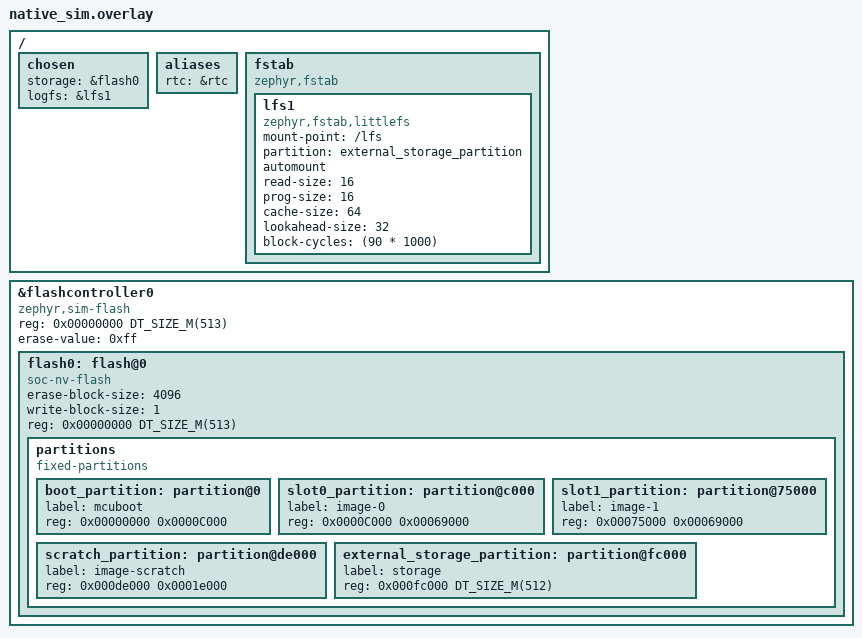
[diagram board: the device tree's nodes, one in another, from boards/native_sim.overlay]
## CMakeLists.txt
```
#-------------------------------------------------------------------------------
# Backplane Power Module Application
#
# Copyright (c) 2023 Launch Initiative
# SPDX-License-Identifier: Apache-2.0

set(FSW_ROOT ${CMAKE_CURRENT_SOURCE_DIR}/../../..)
include(${FSW_ROOT}/cmake/Autocoders.cmake)
include(${FSW_ROOT}/cmake/Snippets.cmake)

AddCommonSnippets()

list(APPEND CONF_FILE ${CMAKE_CURRENT_SOURCE_DIR}/core.conf)

if (DEBUG)
    message(STATUS "Adding debug configuration")
    AddDebugSnippets()
    list(APPEND CONF_FILE ${CMAKE_CURRENT_SOURCE_DIR}/debug.conf)
endif ()

if (BOARD STREQUAL "native_sim")
    if (UNIX AND NOT APPLE)
        message(STATUS "Adding simulation configuration")
        AddSimSnippets()
        list(APPEND CONF_FILE ${CMAKE_CURRENT_SOURCE_DIR}/sim.conf)
    else ()
        message(FATAL_ERROR "Simulation is only supported on Linux systems")
    endif ()
endif ()


cmake_minimum_required(VERSION 3.13.1)
find_package(Zephyr REQUIRED HINTS $ENV{ZEPHYR_BASE})

project(power-module LANGUAGES C CXX)

FILE(GLOB SOURCES src/*.c src/*.cpp)
target_include_directories(app PRIVATE include)
target_sources(app PRIVATE ${SOURCES})

AutocodeTypes(${CMAKE_SOURCE_DIR}/ac/types.yaml)
AutocodeNetworkDefinitions()
add_dependencies(app ac_net_defs ac_types)
```

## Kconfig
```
# Copyright (c) 2024 Launch Initiative
# SPDX-License-Identifier: Apache-2.0

menu "Zephyr"
source "Kconfig.zephyr"
endmenu

config MODULE_ID
    int "Module ID number"
    default 1
    help
      The module ID to use as the fourth octet in the IP address.

module = APP_POWER_MODULE
module-str = APP_POWER_MODULE
source "subsys/logging/Kconfig.template.log_config"
```

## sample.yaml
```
sample:
  description: Power Module
  name: power-module
common:
  build_only: true
  integration_platforms:
    - power_module@2
    - blt_plane
    - native_sim
tests:
  backplane.power_module.debug:
    extra_overlay_confs:
      - debug.conf
      - sim.conf
  backplane.power_module.native_sim:
    extra_overlay_confs:
      - sim.conf
      - debug.conf
```

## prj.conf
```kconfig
# Copyright (c) 2024 RIT Launch Initiative
# SPDX-License-Identifier: Apache-2.0

# ADC
CONFIG_ADC=y
CONFIG_ADC_ASYNC=y

# Clocks
CONFIG_CLOCK_CONTROL=y

# CPP
CONFIG_CPP=y

# Flash
CONFIG_FLASH=y
CONFIG_FLASH_MAP=y
CONFIG_FLASH_PAGE_LAYOUT=y

# Filesystem
CONFIG_DISK_ACCESS=y
CONFIG_FILE_SYSTEM=y
CONFIG_FILE_SYSTEM_LITTLEFS=y
CONFIG_FS_LITTLEFS_FMP_DEV=y

# Hashmap for UDP
CONFIG_SYS_HASH_MAP=y
CONFIG_SYS_HASH_FUNC32=y

# IO
CONFIG_GPIO=y
CONFIG_I2C=y
CONFIG_PINCTRL=y
CONFIG_SERIAL=y
CONFIG_LED=y

# OS
CONFIG_POLL=y
CONFIG_MAIN_STACK_SIZE=4096
CONFIG_STACK_USAGE=y
CONFIG_TIMESLICE_SIZE=50

# State Machine
CONFIG_SMF=y

# SPI
CONFIG_SPI=y
CONFIG_SPI_ASYNC=y
CONFIG_SPI_STM32_INTERRUPT=y
# CONFIG_SPI_STM32_DMA=y
CONFIG_SPI_RTIO=y

# Networking
CONFIG_NETWORKING=y
CONFIG_NET_ARP_TABLE_SIZE=4
CONFIG_NET_CONTEXT_RCVTIMEO=y
CONFIG_NET_DEFAULT_IF_ETHERNET=y
CONFIG_NET_DRIVERS=y
CONFIG_NET_IPV4=y
CONFIG_NET_IPV6=n
CONFIG_NET_L2_ETHERNET=y
CONFIG_NET_L2_ETHERNET_MGMT=y
CONFIG_NET_MAX_CONN=10
CONFIG_NET_SOCKETS=y
CONFIG_NET_STATISTICS=y

# RNG (Needed for networking)
CONFIG_ENTROPY_GENERATOR=y
CONFIG_TEST_RANDOM_GENERATOR=y # TODO: See if its worth using STM32 HW RNG to remove warning

# Sensors
CONFIG_SENSOR=y
CONFIG_SENSOR_ASYNC_API=y
```

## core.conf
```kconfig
# Copyright (c) 2024 RIT Launch Initiative
# SPDX-License-Identifier: Apache-2.0

# CPP
CONFIG_CPP=y
CONFIG_REQUIRES_FULL_LIBCPP=y
CONFIG_STD_CPP20=y

CONFIG_F_CORE=y
CONFIG_F_CORE_DEVICE=y
CONFIG_F_CORE_SENSOR=y
CONFIG_F_CORE_NET=y
CONFIG_F_CORE_OS=y
CONFIG_F_CORE_UTILS=y
CONFIG_CBPRINTF_FP_SUPPORT=y

# Filesystem
CONFIG_FILE_SYSTEM=y
CONFIG_FILE_SYSTEM_LITTLEFS=y
CONFIG_FS_LITTLEFS_FMP_DEV=y
CONFIG_FLASH=y
CONFIG_FLASH_MAP=y
CONFIG_FLASH_PAGE_LAYOUT=y

# OS
CONFIG_POLL=y
CONFIG_MAIN_STACK_SIZE=2048
CONFIG_STACK_USAGE=y

CONFIG_TIMESLICING=y
CONFIG_TIMESLICE_SIZE=20
CONFIG_TIMESLICE_PRIORITY=0
CONFIG_THREAD_STACK_INFO=y

CONFIG_DYNAMIC_THREAD=y
# Max stack size for dynamic threads
CONFIG_DYNAMIC_THREAD_STACK_SIZE=4096
CONFIG_DYNAMIC_THREAD_POOL_SIZE=3
CONFIG_LOG=y

# Networking
CONFIG_NETWORKING=y
CONFIG_NET_ARP_TABLE_SIZE=4
CONFIG_NET_CONTEXT_RCVTIMEO=y
CONFIG_NET_DEFAULT_IF_ETHERNET=y
CONFIG_NET_DRIVERS=y
CONFIG_NET_IPV4=y
CONFIG_NET_IPV6=n
CONFIG_NET_L2_ETHERNET=y
CONFIG_NET_L2_ETHERNET_MGMT=y
CONFIG_NET_MAX_CONN=10
CONFIG_NET_SOCKETS=y
CONFIG_NET_STATISTICS=y
CONFIG_SNTP=y

# RNG (Needed for networking)
CONFIG_ENTROPY_GENERATOR=y
CONFIG_TEST_RANDOM_GENERATOR=y # TODO: See if its worth using STM32 HW RNG to remove warning

# IO
CONFIG_I2C=y
CONFIG_SPI=y
CONFIG_SENSOR=y

# Zbus
CONFIG_ZBUS=y
CONFIG_ZBUS_LOG_LEVEL_INF=y
CONFIG_ZBUS_RUNTIME_OBSERVERS=y
```

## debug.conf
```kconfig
# Copyright (c) 2024 RIT Launch Initiative
# SPDX-License-Identifier: Apache-2.0

# Compiler
CONFIG_DEBUG=y
CONFIG_DEBUG_OPTIMIZATIONS=y
CONFIG_DEBUG_THREAD_INFO=y
CONFIG_THREAD_RUNTIME_STATS=y

# Console
CONFIG_CONSOLE=y
CONFIG_CONSOLE_SUBSYS=y
CONFIG_SERIAL=y
CONFIG_UART_CONSOLE=y

# Shell (common)
CONFIG_SHELL=y
CONFIG_DEVICE_SHELL=y
CONFIG_FILE_SYSTEM_SHELL=y
CONFIG_FLASH_SHELL=y
CONFIG_GPIO_SHELL=y
CONFIG_I2C_SHELL=y
CONFIG_KERNEL_SHELL=y
CONFIG_NET_SHELL=y
CONFIG_SENSOR_SHELL=y
CONFIG_HEAP_MEM_POOL_SIZE=4096
CONFIG_SHELL_BACKEND_SERIAL_API_INTERRUPT_DRIVEN=y
CONFIG_SHELL_BACKEND_SERIAL_TX_RING_BUFFER_SIZE=4096
CONFIG_SHELL_BACKEND_SERIAL_RX_RING_BUFFER_SIZE=4096

# Logging
CONFIG_APP_POWER_MODULE_LOG_LEVEL_DBG=y
CONFIG_LOG=y

# Networking
CONFIG_NET_STATISTICS=y
```

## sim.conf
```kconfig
CONFIG_RTC=y
CONFIG_RTC_EMUL=y
```

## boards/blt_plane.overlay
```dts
/ {
	aliases {
		shunt-batt = &ina0;
		shunt-3v3 = &ina1;
		shunt-5v0 = &ina2;
	};

	fstab {
		compatible = "zephyr,fstab";

		lfs1: lfs1 {
			compatible = "zephyr,fstab,littlefs";
			mount-point = "/lfs";
			partition = <&external_storage_partition>;
			automount;

			read-size = <256>;
			prog-size = <256>;
			cache-size = <512>;
			lookahead-size = <128>;
			block-cycles = <(90 * 1000)>;
		};
	};
};
```

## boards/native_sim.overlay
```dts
/ {
	chosen {
		storage = &flash0;
		logfs = &lfs1;
	};

	aliases {
		rtc = &rtc;
	};

	fstab {
		compatible = "zephyr,fstab";
		lfs1: lfs1 {
			compatible = "zephyr,fstab,littlefs";
			mount-point = "/lfs";
			partition = <&external_storage_partition>;
			automount;

			// the binding reccomends defaults for these
			read-size = <16>;
			prog-size = <16>;
			cache-size = <64>; // may need to grow for optimization
			lookahead-size = <32>;
			block-cycles = <(90 * 1000)>;
			// the datasheet gives 100K P-E cycles
			// NOTE: this seems to default to 512 for the mounted filesystem
			// anyway
		};
	};
};


&flashcontroller0 {
	status = "okay";
	compatible = "zephyr,sim-flash";
	reg = <0x00000000 DT_SIZE_M(513)>;

	#address-cells = <1>;
	#size-cells = <1>;
	erase-value = <0xff>;

	flash0: flash@0 {
		status = "okay";
		compatible = "soc-nv-flash";
		erase-block-size = <4096>;
		write-block-size = <1>;
		reg = <0x00000000 DT_SIZE_M(513)>; // builtin stuff + external flash simulation

		partitions {
			compatible = "fixed-partitions";
			#address-cells = <1>;
			#size-cells = <1>;

			boot_partition: partition@0 {
				label = "mcuboot";
				reg = <0x00000000 0x0000C000>;
			};
			slot0_partition: partition@c000 {
				label = "image-0";
				reg = <0x0000C000 0x00069000>;
			};
			slot1_partition: partition@75000 {
				label = "image-1";
				reg = <0x00075000 0x00069000>;
			};
			scratch_partition: partition@de000 {
				label = "image-scratch";
				reg = <0x000de000 0x0001e000>;
			};
			external_storage_partition: partition@fc000 {
				label = "storage";
				reg = <0x000fc000 DT_SIZE_M(512)>;
			};
		};
	};
};
```

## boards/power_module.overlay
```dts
/ {
	aliases {
		shunt-batt = &ina0;
		shunt-3v3 = &ina1;
		shunt-5v0 = &ina2;
	};
};
```

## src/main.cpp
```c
/*
* Copyright (c) 2024 RIT Launch Initiative
 *
 * SPDX-License-Identifier: Apache-2.0
 */

#include "c_power_module.h"

#include <f_core/os/c_task.h>
#include <f_core/os/n_rtos.h>
#include <n_autocoder_network_defs.h>
#ifdef CONFIG_ARCH_POSIX
#include <nsi_main.h>
#include <signal.h>
#endif

LOG_MODULE_REGISTER(main);

#ifdef CONFIG_ARCH_POSIX
static volatile sig_atomic_t shutdownRequested = 0;

static void NativeSimSignalHandler(int) { shutdownRequested = 1; }
#endif

int main() {
    static CPowerModule powerModule{};

    powerModule.AddTenantsToTasks();
    powerModule.AddTasksToRtos();
    powerModule.SetupCallbacks();

    NRtos::StartRtos();

#ifdef CONFIG_ARCH_POSIX
    signal(SIGINT, NativeSimSignalHandler);
    signal(SIGTERM, NativeSimSignalHandler);

    while (!shutdownRequested) {
        k_sleep(K_MSEC(100));
    }

    NRtos::StopRtos();
    powerModule.Cleanup();
    nsi_exit(0);
#endif

    return 0;
}
```

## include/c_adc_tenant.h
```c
#ifndef C_ADC_TENANT_H
#define C_ADC_TENANT_H

#include <n_autocoder_types.h>

#include <f_core/messaging/c_message_port.h>
#include <f_core/device/c_adc.h>
#include <f_core/os/c_tenant.h>

#include <zephyr/devicetree.h>

class CAdcTenant : public CTenant {
public:
    explicit CAdcTenant(const char* name, CMessagePort<int32_t> &dataToBroadcast, CMessagePort<int32_t> &dataToLog)
        : CTenant(name), dataToBroadcast(dataToBroadcast), dataToLog(dataToLog)
    {
    }

    ~CAdcTenant() override = default;

    void Startup() override;

    void PostStartup() override;

    void Run() override;

private:
    CAdc adc = CAdc(ADC_DT_SPEC_GET_BY_IDX(DT_PATH(zephyr_user), 0));
    CMessagePort<int32_t> &dataToBroadcast;
    CMessagePort<int32_t> &dataToLog;
};

#endif //C_ADC_TENANT_H
```

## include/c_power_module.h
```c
#pragma once

#include "c_sensing_tenant.h"

#include <n_autocoder_types.h>

// F-Core Includes
#include <f_core/c_project_configuration.h>
#include <f_core/device/c_rtc.h>
#include <f_core/messaging/c_message_port.h>
#include <f_core/net/application/c_udp_alert_tenant.h>
#include <f_core/net/application/c_udp_broadcast_tenant.h>
#include <f_core/os/c_task.h>
#include <f_core/os/tenants/c_datalogger_tenant.h>
#include <n_autocoder_network_defs.h>

class CPowerModule : public CProjectConfiguration {
  public:
    /**
     * Constructor
     */
    CPowerModule();

    /**
     * See parent docs
     */
    void AddTenantsToTasks() override;

    /**
     * See parent docs
     */
    void AddTasksToRtos() override;

    /**
     * See parent docs
     */
    void SetupCallbacks() override;

    /**
     * See parent docs
     */
    void Cleanup();

  private:
    std::string ipAddrStr = CREATE_IP_ADDR(NNetworkDefs::POWER_MODULE_IP_ADDR_BASE, 2, CONFIG_MODULE_ID);
    const char* sntpServerAddr = "10.2.1.1";
    // TODO: Maybe we should look into hostnames?
    static constexpr int telemetryBroadcastPort = NNetworkDefs::POWER_MODULE_INA_DATA_PORT;
    static constexpr int downlinkBroadcastPort = NNetworkDefs::POWER_MODULE_DOWNLINK_DATA_PORT;

    // Devices
    CRtc rtc{*DEVICE_DT_GET(DT_ALIAS(rtc))};

    // Message Ports
    CMessagePort<NTypes::SensorData>& sensorDataBroadcastMessagePort;
    CMessagePort<NTypes::TimestampedSensorData>& sensorDataLogMessagePort;
    CMessagePort<NTypes::LoRaBroadcastSensorData>& sensorDataDownlinkMessagePort;

    // Tenants
    CSensingTenant sensingTenant{"Sensing Tenant", sensorDataBroadcastMessagePort, sensorDataLogMessagePort,
                                 sensorDataDownlinkMessagePort};
    CUdpBroadcastTenant<NTypes::SensorData> broadcastTenant{"Broadcast Tenant", ipAddrStr.c_str(),
                                                            telemetryBroadcastPort, telemetryBroadcastPort,
                                                            sensorDataBroadcastMessagePort};
    CUdpBroadcastTenant<NTypes::LoRaBroadcastSensorData> downlinkBroadcastTenant{
        "Broadcast Tenant", ipAddrStr.c_str(), downlinkBroadcastPort, downlinkBroadcastPort,
        sensorDataDownlinkMessagePort};

    CDataLoggerTenant<NTypes::TimestampedSensorData> dataLoggerTenant{
        "Data Logger Tenant", "/lfs/sensor_data.bin", LogMode::Growing, 0, sensorDataLogMessagePort, K_SECONDS(60), 5};
    CUdpAlertTenant alertTenant{"Alert Tenant", ipAddrStr.c_str(), NNetworkDefs::ALERT_PORT};

    // Tasks
    // 68.1 ms based on our devicetree configuration, and we don't need to sample that quickly
    static constexpr int ina219SampleTimeMillis = 69;

    CTask networkTask{"Networking Task", 15, 3072, ina219SampleTimeMillis};
    CTask sensingTask{"Sensing Task", 15, 2048, ina219SampleTimeMillis};
    CTask dataLoggingTask{"Data Logging Task", 15, 2048, 0};
};
```

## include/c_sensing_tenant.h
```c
#pragma once

#include "f_core/device/c_rtc.h"

#include <f_core/messaging/c_message_port.h>
#include <f_core/os/c_runnable_tenant.h>
#include <f_core/utils/c_observer.h>
#include <f_core/utils/c_soft_timer.h>
#include <n_autocoder_types.h>

class CSensingTenant : public CRunnableTenant, public CObserver {
  public:
    explicit CSensingTenant(const char *name, CMessagePort<NTypes::SensorData> &dataToBroadcast,
                            CMessagePort<NTypes::TimestampedSensorData> &dataToLog,
                            CMessagePort<NTypes::LoRaBroadcastSensorData> &dataToDownlink)
        : CRunnableTenant(name), dataToBroadcast(dataToBroadcast), dataToLog(dataToLog),
          dataToDownlink(dataToDownlink) {}

    ~CSensingTenant() override = default;

    void Startup() override;

    void PostStartup() override;

    void Run() override;

    void Notify(void *ctx) override;

  private:
    CMessagePort<NTypes::SensorData> &dataToBroadcast;
    CMessagePort<NTypes::TimestampedSensorData> &dataToLog;
    CMessagePort<NTypes::LoRaBroadcastSensorData> &dataToDownlink;
    CSoftTimer timer{nullptr, nullptr};
    CRtc rtc{*DEVICE_DT_GET(DT_ALIAS(rtc))};

    void sendDownlinkData(const NTypes::SensorData &data);
};
```

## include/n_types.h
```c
#ifndef N_TYPES_H
#define N_TYPES_H
#include <f_core/types.h>

namespace NTypes {
struct __attribute__((packed)) SensorData {
    NSensor::ShuntData RailBattery;
    NSensor::ShuntData Rail3v3;
    NSensor::ShuntData Rail5v0;
};
}

#endif //N_TYPES_H
```

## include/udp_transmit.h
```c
#ifndef POWER_MODULE_UDP_TRANSMIT_H
#define POWER_MODULE_UDP_TRANSMIT_H

#include <stddef.h>
#include <stdint.h>

struct zbus_channel;
void transmitRawData(const struct zbus_channel* chan);

void transmitDownlinkData(const struct zbus_channel* chan);

#endif //POWER_MODULE_UDP_TRANSMIT_H
```

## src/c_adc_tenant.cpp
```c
#include "c_adc_tenant.h"

#include <f_core/device/c_adc.h>
#include <zephyr/logging/log.h>

LOG_MODULE_REGISTER(CAdcTenant);

void CAdcTenant::Startup() {
}

void CAdcTenant::PostStartup() {
}

void CAdcTenant::Run() {
    if (adc.UpdateAdcValue() < 0) {
        LOG_DBG("Skipping ADC read");
        return;
    }

    int32_t vin_sense = adc.GetAdcValue(); // Gets RAW ADC value

    int32_t vin = vin_sense * 11.1; // Math according to doc scematic

    dataToBroadcast.Send(vin, K_MSEC(5));
    dataToLog.Send(vin, K_MSEC(5));
}
```

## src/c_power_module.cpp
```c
#include "c_power_module.h"

#include <n_autocoder_types.h>

// F-Core Tenant
#include <f_core/messaging/c_latest_message_port.h>
#include <f_core/messaging/c_msgq_message_port.h>
#include <f_core/os/n_rtos.h>
#include <f_core/utils/n_time_utils.h>

static auto telemetryBroadcastMessagePort = CLatestMessagePort<NTypes::SensorData>();
static auto downlinkMessageMessagePort = CLatestMessagePort<NTypes::LoRaBroadcastSensorData>();

K_MSGQ_DEFINE(dataLogQueue, sizeof(NTypes::TimestampedSensorData), 512, 4);
static auto dataLogMsgQueue = CMsgqMessagePort<NTypes::TimestampedSensorData>(dataLogQueue);

CPowerModule::CPowerModule()
    : CProjectConfiguration(), sensorDataBroadcastMessagePort(telemetryBroadcastMessagePort),
      sensorDataLogMessagePort(dataLogMsgQueue), sensorDataDownlinkMessagePort(downlinkMessageMessagePort) {}

void CPowerModule::AddTenantsToTasks() {
    // Networking
    networkTask.AddTenant(broadcastTenant);
    networkTask.AddTenant(downlinkBroadcastTenant);

    // Sensing
    sensingTask.AddTenant(sensingTenant);

    // Data Logging
    dataLoggingTask.AddTenant(dataLoggerTenant);
}

void CPowerModule::AddTasksToRtos() {
    // Networking
    NRtos::AddTask(networkTask);

    // Sensing
    NRtos::AddTask(sensingTask);

    // Data Logging
    NRtos::AddTask(dataLoggingTask);
}

void CPowerModule::SetupCallbacks() {
    alertTenant.Subscribe(&sensingTenant);
    alertTenant.Register();

    // Not a callback, but ¯\_(ツ)_/¯
    // Maybe have Add and Setup tasks be private and have main.cpp call a single function?
    // Configuration children would call CBase::Setup and then can add their own setup below
    NTimeUtils::SntpSynchronize(rtc, sntpServerAddr, 5, K_MSEC(100));
}

void CPowerModule::Cleanup() { dataLoggerTenant.Cleanup(); }
```

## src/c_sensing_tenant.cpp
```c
#include "c_sensing_tenant.h"

#include "c_power_module.h"

#include <f_core/device/sensor/c_shunt.h>
#include <f_core/n_alerts.h>
#include <zephyr/logging/log.h>

LOG_MODULE_REGISTER(CSensingTenant);

void CSensingTenant::Startup() {
    static constexpr uint32_t minuteInMillis = 1000 * 60;
    timer.StartTimer(minuteInMillis, 0); // Log every minute on the pad
}

void CSensingTenant::PostStartup() {}

void CSensingTenant::Run() {
    NTypes::TimestampedSensorData timestampedData{
        .timestamp = 0,
        .data = {.RailBattery = {.Voltage = 0.0f, .Current = 0.0f, .Power = 0.0f},
                 .Rail3v3 = {.Voltage = 0.0f, .Current = 0.0f, .Power = 0.0f},
                 .Rail5v0 = {.Voltage = 0.0f, .Current = 0.0f, .Power = 0.0f}}};

    NTypes::SensorData& data = timestampedData.data;

#ifndef CONFIG_ARCH_POSIX
    CShunt shuntBatt(*DEVICE_DT_GET(DT_ALIAS(shunt_batt)));
    CShunt shunt3v3(*DEVICE_DT_GET(DT_ALIAS(shunt_3v3)));
    CShunt shunt5v0(*DEVICE_DT_GET(DT_ALIAS(shunt_5v0)));
    CSensorDevice* sensors[] = {&shuntBatt, &shunt3v3, &shunt5v0};
#endif

#ifndef CONFIG_ARCH_POSIX
    int i = 0;
    for (auto sensor : sensors) {
        if (!sensor->UpdateSensorValue()) {
            LOG_ERR("Failed to update sensor value for %d", i);
        }
        i++;
    }

    // Note that compilers don't accept references to packed struct fields
    uint32_t tmpTimestamp = 0;
    if (int ret = rtc.GetMillisTime(tmpTimestamp); ret < 0) {
        LOG_ERR("Failed to get time from RTC (%d)", ret);
    } else {
        timestampedData.timestamp = tmpTimestamp;
    }

    // NOTE: The below calibration values were determined based on using a load tester
    // Zephyr does not support inputting floats into the LSB microamp offset, so we must do it manually
    static constexpr float extra3VCalibrationMultiplier = 0.885f;
    data.Rail3v3.Current = shunt3v3.GetSensorValueFloat(SENSOR_CHAN_CURRENT) * extra3VCalibrationMultiplier;
    data.Rail3v3.Voltage = shunt3v3.GetSensorValueFloat(SENSOR_CHAN_VOLTAGE);
    data.Rail3v3.Power = data.Rail3v3.Current * data.Rail3v3.Voltage;

    static constexpr float extra5VCalibrationMultiplier = 0.980f;
    data.Rail5v0.Current = shunt5v0.GetSensorValueFloat(SENSOR_CHAN_CURRENT) * extra5VCalibrationMultiplier;

    data.Rail5v0.Voltage = shunt5v0.GetSensorValueFloat(SENSOR_CHAN_VOLTAGE);
    data.Rail5v0.Power = data.Rail5v0.Current * data.Rail5v0.Voltage;

    static constexpr float extraBattCalibrationMultiplier = 0.962f;
    data.RailBattery.Current = shuntBatt.GetSensorValueFloat(SENSOR_CHAN_CURRENT) * extraBattCalibrationMultiplier;
    data.RailBattery.Voltage = shuntBatt.GetSensorValueFloat(SENSOR_CHAN_VOLTAGE);
    data.RailBattery.Power = data.RailBattery.Current * data.RailBattery.Voltage;
#endif

    dataToBroadcast.Send(data, K_MSEC(5));
    sendDownlinkData(data);

    if (timer.IsExpired()) {
        dataToLog.Send(timestampedData, K_MSEC(5));
        NRtos::ResumeTask("Data Logging Task");
    }
}

void CSensingTenant::Notify(void* ctx) {
    // TODO: Knock, knock! Race condition...
    switch (*static_cast<NAlerts::AlertType*>(ctx)) {
        case NAlerts::BOOST:
            LOG_INF("Boost detected. Logging data.");
            timer.StartTimer(500); // Log every half a second during flight
            break;

        case NAlerts::LANDED:
            LOG_INF("Landing detected. Disabling logging.");
            timer.StopTimer(); // Stop logging
            break;

        default:
            return;
    }
}

void CSensingTenant::sendDownlinkData(const NTypes::SensorData& data) {
    NTypes::LoRaBroadcastSensorData downlinkData{
        .RailBattery = {.Voltage = static_cast<int16_t>(CSensorDevice::ToMilliUnits(data.RailBattery.Voltage)),
                        .Current = static_cast<int16_t>(CSensorDevice::ToMilliUnits(data.RailBattery.Current)),
                        .Power = static_cast<int16_t>(CSensorDevice::ToMilliUnits(data.RailBattery.Power))},
        .Rail3v3 = {.Voltage = static_cast<int16_t>(CSensorDevice::ToMilliUnits(data.Rail3v3.Voltage)),
                    .Current = static_cast<int16_t>(CSensorDevice::ToMilliUnits(data.Rail3v3.Current)),
                    .Power = static_cast<int16_t>(CSensorDevice::ToMilliUnits(data.Rail3v3.Power))}};

    dataToDownlink.Send(downlinkData, K_MSEC(5));
}
```

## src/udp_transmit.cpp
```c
#include "udp_transmit.h"

#include "zephyr/zbus/zbus.h"

#include <string>
#include <f_core/utils/c_hashmap.h>
#include <f_core/net/transport/c_udp_socket.h>

void transmitRawData(const struct zbus_channel* chan) {
    CHashMap<std::string, CUdpSocket> udpSockets = static_cast<CHashMap<std::string, CUdpSocket>>(zbus_chan_user_data(chan));
    udpSockets.Get("telemetry")->TransmitAsynchronous(zbus_chan_const_msg(chan), zbus_chan_msg_size(chan));
}

void transmitDownlinkData(const struct zbus_channel* chan) {
    CHashMap<std::string, CUdpSocket> udpSockets = static_cast<CHashMap<std::string, CUdpSocket>>(zbus_chan_user_data(chan));
    udpSockets.Get("downlink")->TransmitAsynchronous(zbus_chan_const_msg(chan), zbus_chan_msg_size(chan));
}
```
